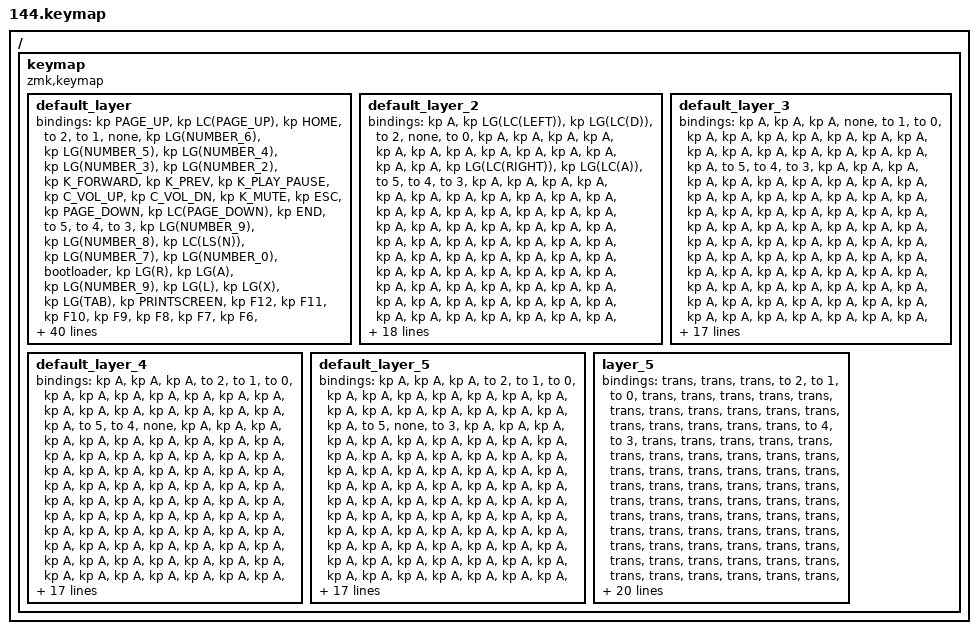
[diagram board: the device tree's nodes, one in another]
#include <behaviors.dtsi>
#include <dt-bindings/zmk/keys.h>

/ {
    keymap {
        compatible = "zmk,keymap";

        default_layer {
            // --------------------------------------------------------------------------------------------------------------------------------------------------------------------
            // |   ESC   |    Q    |    W    |    E    |    R    |    T    |                                          |    Y    |    U    |    I    |    O    |    P    |    \    |
            // |   TAB   |    A    |    S    |    D    |    F    |    G    |                                          |    H    |    J    |    K    |    L    |    ;    |    '    |
            // |  SHIFT  |    Z    |    X    |    C    |    V    |    B    | CTRL+A  | CTRL+C  |  |  CTRL+V |  CTRL+X |    N    |    M    |    ,    |    .    |    /    |  R CTRL |
            //                               |   GUI   |   DEL   | RETURN  |  SPACE  | ESCAPE  |  |  RETURN |  SPACE  |   TAB   |   BSPC  |  R ALT  |

            bindings = <
&kp PAGE_UP      &kp LC(PAGE_UP)    &kp HOME          &to 2          &to 1          &none         &kp LG(NUMBER_6)  &kp LG(NUMBER_5)  &kp LG(NUMBER_4)  &kp LG(NUMBER_3)  &kp LG(NUMBER_2)  &kp K_FORWARD    &kp K_PREV    &kp K_PLAY_PAUSE  &kp C_VOL_UP      &kp C_VOL_DN  &kp K_MUTE    &kp ESC
&kp PAGE_DOWN    &kp LC(PAGE_DOWN)  &kp END           &to 5          &to 4          &to 3         &kp LG(NUMBER_9)  &kp LG(NUMBER_8)  &kp LC(LS(N))     &kp LG(NUMBER_7)  &kp LG(NUMBER_0)  &bootloader      &kp LG(R)     &kp LG(A)         &kp LG(NUMBER_9)  &kp LG(L)     &kp LG(X)     &kp LG(TAB)
&kp PRINTSCREEN  &kp F12            &kp F11           &kp F10        &kp F9         &kp F8        &kp F7            &kp F6            &kp LC(A)         &kp DELETE        &kp SCROLLLOCK    &kp INS          &kp F5        &kp F4            &kp F3            &kp F2        &kp F1        &none
&kp BSPC         &kp EQUAL          &kp MINUS         &kp NUMBER_0   &kp NUMBER_9   &kp NUMBER_8  &kp NUMBER_7      &kp NUMBER_6      &kp KP_DIVIDE     &kp LC(LS(S))     &kp LS(LC(Y))     &kp KP_NUMLOCK   &kp NUMBER_5  &kp NUMBER_4      &kp NUMBER_3      &kp NUMBER_2  &kp NUMBER_1  &kp GRAVE
&kp BACKSLASH    &kp RIGHT_BRACKET  &kp LEFT_BRACKET  &kp P          &kp O          &kp I         &kp U             &kp Y             &kp STAR          &kp KP_NUMBER_9   &kp KP_NUMBER_8   &kp KP_NUMBER_7  &kp T         &kp R             &kp E             &kp W         &kp Q         &kp TAB
&kp LG(E)        &kp ENTER          &kp SINGLE_QUOTE  &kp SEMICOLON  &kp L          &kp K         &kp J             &kp H             &kp KP_MINUS      &kp KP_NUMBER_6   &kp KP_NUMBER_5   &kp KP_NUMBER_4  &kp G         &kp F             &kp D             &kp S         &kp A         &kp CAPSLOCK
&none            &kp UP_ARROW       &kp RIGHT_SHIFT   &kp SLASH      &kp DOT        &kp COMMA     &kp M             &kp N             &kp KP_PLUS       &kp KP_NUMBER_3   &kp KP_NUMBER_2   &kp KP_NUMBER_1  &kp B         &kp V             &kp C             &kp X         &kp Z         &kp LEFT_SHIFT
&kp RIGHT_ARROW  &kp DOWN_ARROW     &kp LEFT_ARROW    &kp RCTRL      &kp RIGHT_ALT  &none         &kp SPACE         &none             &kp KP_ENTER      &kp KP_DOT        &kp KP_NUMBER_0   &kp KP_NUMBER_0  &kp SPACE     &kp LC(Y)         &kp LC(Z)         &kp LEFT_ALT  &kp LEFT_GUI  &kp LCTRL
&kp W            &kp G              &kp M             &kp H          &kp B          &kp D         &kp N7            &kp N8            &kp S             &kp N9            &kp I             &kp NUMBER_6     &kp Y         &kp NUMBER_5      &kp NUMBER_4
&kp NUMBER_2     &kp NUMBER_3       &kp NUMBER_8      &kp NUMBER_7   &kp NUMBER_5   &kp C         &kp NUMBER_0      &kp NUMBER_6      &kp NUMBER_2      &kp NUMBER_4      &kp L             &kp NUMBER_3                                                       &kp NUMBER_4  &kp NUMBER_1  &kp O
            >;

            sensor-bindings = <&inc_dec_kp C_VOL_UP C_VOL_DN &inc_dec_kp PG_UP PG_DN &inc_dec_kp C_VOL_UP C_VOL_DN &inc_dec_kp PG_UP PG_DN &inc_dec_kp C_VOL_UP C_VOL_DN &inc_dec_kp PG_UP PG_DN>;
        };

        default_layer_2 {
            // --------------------------------------------------------------------------------------------------------------------------------------------------------------------
            // |   ESC   |    Q    |    W    |    E    |    R    |    T    |                                          |    Y    |    U    |    I    |    O    |    P    |    \    |
            // |   TAB   |    A    |    S    |    D    |    F    |    G    |                                          |    H    |    J    |    K    |    L    |    ;    |    '    |
            // |  SHIFT  |    Z    |    X    |    C    |    V    |    B    | CTRL+A  | CTRL+C  |  |  CTRL+V |  CTRL+X |    N    |    M    |    ,    |    .    |    /    |  R CTRL |
            //                               |   GUI   |   DEL   | RETURN  |  SPACE  | ESCAPE  |  |  RETURN |  SPACE  |   TAB   |   BSPC  |  R ALT  |

            bindings = <
&kp A  &kp LG(LC(LEFT))   &kp LG(LC(D))  &to 2  &none  &to 0  &kp A  &kp A  &kp A  &kp A  &kp A  &kp A  &kp A  &kp A  &kp A  &kp A  &kp A  &kp A
&kp A  &kp LG(LC(RIGHT))  &kp LG(LC(A))  &to 5  &to 4  &to 3  &kp A  &kp A  &kp A  &kp A  &kp A  &kp A  &kp A  &kp A  &kp A  &kp A  &kp A  &kp A
&kp A  &kp A              &kp A          &kp A  &kp A  &kp A  &kp A  &kp A  &kp A  &kp A  &kp A  &kp A  &kp A  &kp A  &kp A  &kp A  &kp A  &kp A
&kp A  &kp A              &kp A          &kp A  &kp A  &kp A  &kp A  &kp A  &kp A  &kp A  &kp A  &kp A  &kp A  &kp A  &kp A  &kp A  &kp A  &kp A
&kp A  &kp A              &kp A          &kp A  &kp A  &kp A  &kp A  &kp A  &kp A  &kp A  &kp A  &kp A  &kp A  &kp A  &kp A  &kp A  &kp A  &kp A
&kp A  &kp A              &kp A          &kp A  &kp A  &kp A  &kp A  &kp A  &kp A  &kp A  &kp A  &kp A  &kp A  &kp A  &kp A  &kp A  &kp A  &kp A
&none  &kp A              &kp A          &kp A  &kp A  &kp A  &kp A  &kp A  &kp A  &kp A  &kp A  &kp A  &kp A  &kp A  &kp A  &kp A  &kp A  &kp A
&kp A  &kp A              &kp A          &kp A  &kp A  &kp A  &kp A  &kp A  &kp A  &kp A  &kp A  &kp A  &kp A  &kp A  &kp A  &kp A  &kp A  &kp A
&kp A  &kp A              &kp A          &none  &kp A  &kp A  &kp A  &kp A  &none  &kp A  &kp A  &kp A  &kp A  &none  &kp A
&none  &kp A              &kp A          &kp A  &kp A  &none  &kp A  &kp A  &kp A  &kp A  &none  &kp A                       &kp A  &kp A  &kp A
            >;

            sensor-bindings = <&inc_dec_kp C_VOL_UP C_VOL_DN &inc_dec_kp PG_UP PG_DN &inc_dec_kp C_VOL_UP C_VOL_DN &inc_dec_kp PG_UP PG_DN &inc_dec_kp C_VOL_UP C_VOL_DN &inc_dec_kp PG_UP PG_DN>;
        };

        default_layer_3 {
            // --------------------------------------------------------------------------------------------------------------------------------------------------------------------
            // |   ESC   |    Q    |    W    |    E    |    R    |    T    |                                          |    Y    |    U    |    I    |    O    |    P    |    \    |
            // |   TAB   |    A    |    S    |    D    |    F    |    G    |                                          |    H    |    J    |    K    |    L    |    ;    |    '    |
            // |  SHIFT  |    Z    |    X    |    C    |    V    |    B    | CTRL+A  | CTRL+C  |  |  CTRL+V |  CTRL+X |    N    |    M    |    ,    |    .    |    /    |  R CTRL |
            //                               |   GUI   |   DEL   | RETURN  |  SPACE  | ESCAPE  |  |  RETURN |  SPACE  |   TAB   |   BSPC  |  R ALT  |

            bindings = <
&kp A  &kp A  &kp A  &none  &to 1  &to 0  &kp A  &kp A  &kp A  &kp A  &kp A  &kp A  &kp A  &kp A  &kp A  &kp A  &kp A  &kp A
&kp A  &kp A  &kp A  &to 5  &to 4  &to 3  &kp A  &kp A  &kp A  &kp A  &kp A  &kp A  &kp A  &kp A  &kp A  &kp A  &kp A  &kp A
&kp A  &kp A  &kp A  &kp A  &kp A  &kp A  &kp A  &kp A  &kp A  &kp A  &kp A  &kp A  &kp A  &kp A  &kp A  &kp A  &kp A  &kp A
&kp A  &kp A  &kp A  &kp A  &kp A  &kp A  &kp A  &kp A  &kp A  &kp A  &kp A  &kp A  &kp A  &kp A  &kp A  &kp A  &kp A  &kp A
&kp A  &kp A  &kp A  &kp A  &kp A  &kp A  &kp A  &kp A  &kp A  &kp A  &kp A  &kp A  &kp A  &kp A  &kp A  &kp A  &kp A  &kp A
&kp A  &kp A  &kp A  &kp A  &kp A  &kp A  &kp A  &kp A  &kp A  &kp A  &kp A  &kp A  &kp A  &kp A  &kp A  &kp A  &kp A  &kp A
&none  &kp A  &kp A  &kp A  &kp A  &kp A  &kp A  &kp A  &kp A  &kp A  &kp A  &kp A  &kp A  &kp A  &kp A  &kp A  &kp A  &kp A
&kp A  &kp A  &kp A  &kp A  &kp A  &kp A  &kp A  &kp A  &kp A  &kp A  &kp A  &kp A  &kp A  &kp A  &kp A  &kp A  &kp A  &kp A
&kp A  &kp A  &kp A  &none  &kp A  &kp A  &kp A  &kp A  &none  &kp A  &kp A  &kp A  &kp A  &none  &kp A
&none  &kp A  &kp A  &kp A  &kp A  &none  &kp A  &kp A  &kp A  &kp A  &none  &kp A                       &kp A  &kp A  &kp A
            >;

            sensor-bindings = <&inc_dec_kp C_VOL_UP C_VOL_DN &inc_dec_kp PG_UP PG_DN &inc_dec_kp C_VOL_UP C_VOL_DN &inc_dec_kp PG_UP PG_DN &inc_dec_kp C_VOL_UP C_VOL_DN &inc_dec_kp PG_UP PG_DN>;
        };

        default_layer_4 {
            // --------------------------------------------------------------------------------------------------------------------------------------------------------------------
            // |   ESC   |    Q    |    W    |    E    |    R    |    T    |                                          |    Y    |    U    |    I    |    O    |    P    |    \    |
            // |   TAB   |    A    |    S    |    D    |    F    |    G    |                                          |    H    |    J    |    K    |    L    |    ;    |    '    |
            // |  SHIFT  |    Z    |    X    |    C    |    V    |    B    | CTRL+A  | CTRL+C  |  |  CTRL+V |  CTRL+X |    N    |    M    |    ,    |    .    |    /    |  R CTRL |
            //                               |   GUI   |   DEL   | RETURN  |  SPACE  | ESCAPE  |  |  RETURN |  SPACE  |   TAB   |   BSPC  |  R ALT  |

            bindings = <
&kp A  &kp A  &kp A  &to 2  &to 1  &to 0  &kp A  &kp A  &kp A  &kp A  &kp A  &kp A  &kp A  &kp A  &kp A  &kp A  &kp A  &kp A
&kp A  &kp A  &kp A  &to 5  &to 4  &none  &kp A  &kp A  &kp A  &kp A  &kp A  &kp A  &kp A  &kp A  &kp A  &kp A  &kp A  &kp A
&kp A  &kp A  &kp A  &kp A  &kp A  &kp A  &kp A  &kp A  &kp A  &kp A  &kp A  &kp A  &kp A  &kp A  &kp A  &kp A  &kp A  &kp A
&kp A  &kp A  &kp A  &kp A  &kp A  &kp A  &kp A  &kp A  &kp A  &kp A  &kp A  &kp A  &kp A  &kp A  &kp A  &kp A  &kp A  &kp A
&kp A  &kp A  &kp A  &kp A  &kp A  &kp A  &kp A  &kp A  &kp A  &kp A  &kp A  &kp A  &kp A  &kp A  &kp A  &kp A  &kp A  &kp A
&kp A  &kp A  &kp A  &kp A  &kp A  &kp A  &kp A  &kp A  &kp A  &kp A  &kp A  &kp A  &kp A  &kp A  &kp A  &kp A  &kp A  &kp A
&none  &kp A  &kp A  &kp A  &kp A  &kp A  &kp A  &kp A  &kp A  &kp A  &kp A  &kp A  &kp A  &kp A  &kp A  &kp A  &kp A  &kp A
&kp A  &kp A  &kp A  &kp A  &kp A  &kp A  &kp A  &kp A  &kp A  &kp A  &kp A  &kp A  &kp A  &kp A  &kp A  &kp A  &kp A  &kp A
&kp A  &kp A  &kp A  &none  &kp A  &kp A  &kp A  &kp A  &none  &kp A  &kp A  &kp A  &kp A  &none  &kp A
&none  &kp A  &kp A  &kp A  &kp A  &none  &kp A  &kp A  &kp A  &kp A  &none  &kp A                       &kp A  &kp A  &kp A
            >;

            sensor-bindings = <&inc_dec_kp C_VOL_UP C_VOL_DN &inc_dec_kp PG_UP PG_DN &inc_dec_kp C_VOL_UP C_VOL_DN &inc_dec_kp PG_UP PG_DN &inc_dec_kp C_VOL_UP C_VOL_DN &inc_dec_kp PG_UP PG_DN>;
        };

        default_layer_5 {
            // --------------------------------------------------------------------------------------------------------------------------------------------------------------------
            // |   ESC   |    Q    |    W    |    E    |    R    |    T    |                                          |    Y    |    U    |    I    |    O    |    P    |    \    |
            // |   TAB   |    A    |    S    |    D    |    F    |    G    |                                          |    H    |    J    |    K    |    L    |    ;    |    '    |
            // |  SHIFT  |    Z    |    X    |    C    |    V    |    B    | CTRL+A  | CTRL+C  |  |  CTRL+V |  CTRL+X |    N    |    M    |    ,    |    .    |    /    |  R CTRL |
            //                               |   GUI   |   DEL   | RETURN  |  SPACE  | ESCAPE  |  |  RETURN |  SPACE  |   TAB   |   BSPC  |  R ALT  |

            bindings = <
&kp A  &kp A  &kp A  &to 2  &to 1  &to 0  &kp A  &kp A  &kp A  &kp A  &kp A  &kp A  &kp A  &kp A  &kp A  &kp A  &kp A  &kp A
&kp A  &kp A  &kp A  &to 5  &none  &to 3  &kp A  &kp A  &kp A  &kp A  &kp A  &kp A  &kp A  &kp A  &kp A  &kp A  &kp A  &kp A
&kp A  &kp A  &kp A  &kp A  &kp A  &kp A  &kp A  &kp A  &kp A  &kp A  &kp A  &kp A  &kp A  &kp A  &kp A  &kp A  &kp A  &kp A
&kp A  &kp A  &kp A  &kp A  &kp A  &kp A  &kp A  &kp A  &kp A  &kp A  &kp A  &kp A  &kp A  &kp A  &kp A  &kp A  &kp A  &kp A
&kp A  &kp A  &kp A  &kp A  &kp A  &kp A  &kp A  &kp A  &kp A  &kp A  &kp A  &kp A  &kp A  &kp A  &kp A  &kp A  &kp A  &kp A
&kp A  &kp A  &kp A  &kp A  &kp A  &kp A  &kp A  &kp A  &kp A  &kp A  &kp A  &kp A  &kp A  &kp A  &kp A  &kp A  &kp A  &kp A
&none  &kp A  &kp A  &kp A  &kp A  &kp A  &kp A  &kp A  &kp A  &kp A  &kp A  &kp A  &kp A  &kp A  &kp A  &kp A  &kp A  &kp A
&kp A  &kp A  &kp A  &kp A  &kp A  &kp A  &kp A  &kp A  &kp A  &kp A  &kp A  &kp A  &kp A  &kp A  &kp A  &kp A  &kp A  &kp A
&kp A  &kp A  &kp A  &none  &kp A  &kp A  &kp A  &kp A  &none  &kp A  &kp A  &kp A  &kp A  &none  &kp A
&none  &kp A  &kp A  &kp A  &kp A  &none  &kp A  &kp A  &kp A  &kp A  &none  &kp A                       &kp A  &kp A  &kp A
            >;

            sensor-bindings = <&inc_dec_kp C_VOL_UP C_VOL_DN &inc_dec_kp PG_UP PG_DN &inc_dec_kp C_VOL_UP C_VOL_DN &inc_dec_kp PG_UP PG_DN &inc_dec_kp C_VOL_UP C_VOL_DN &inc_dec_kp PG_UP PG_DN>;
        };

        layer_5 {
            bindings = <
&trans  &trans  &trans  &to 2   &to 1   &to 0   &trans  &trans  &trans  &trans  &trans  &trans  &trans  &trans  &trans  &trans  &trans  &trans
&trans  &trans  &trans  &trans  &to 4   &to 3   &trans  &trans  &trans  &trans  &trans  &trans  &trans  &trans  &trans  &trans  &trans  &trans
&trans  &trans  &trans  &trans  &trans  &trans  &trans  &trans  &trans  &trans  &trans  &trans  &trans  &trans  &trans  &trans  &trans  &trans
&trans  &trans  &trans  &trans  &trans  &trans  &trans  &trans  &trans  &trans  &trans  &trans  &trans  &trans  &trans  &trans  &trans  &trans
&trans  &trans  &trans  &trans  &trans  &trans  &trans  &trans  &trans  &trans  &trans  &trans  &trans  &trans  &trans  &trans  &trans  &trans
&trans  &trans  &trans  &trans  &trans  &trans  &trans  &trans  &trans  &trans  &trans  &trans  &trans  &trans  &trans  &trans  &trans  &trans
&none   &trans  &trans  &trans  &trans  &trans  &trans  &trans  &trans  &trans  &trans  &trans  &trans  &trans  &trans  &trans  &trans  &trans
&trans  &trans  &trans  &trans  &trans  &trans  &trans  &trans  &trans  &trans  &trans  &trans  &trans  &trans  &trans  &trans  &trans  &trans
&trans  &trans  &trans  &none   &trans  &trans  &trans  &trans  &none   &trans  &trans  &trans  &trans  &none   &trans
&none   &trans  &trans  &trans  &trans  &none   &trans  &trans  &trans  &trans  &none   &trans                          &trans  &trans  &trans
            >;

            sensor-bindings =
                <&inc_dec_kp 0 0>,
                <&inc_dec_kp 0 0>,
                <&inc_dec_kp 0 0>,
                <&inc_dec_kp 0 0>,
                <&inc_dec_kp 0 0>,
                <&inc_dec_kp 0 0>;
        };
    };
};
